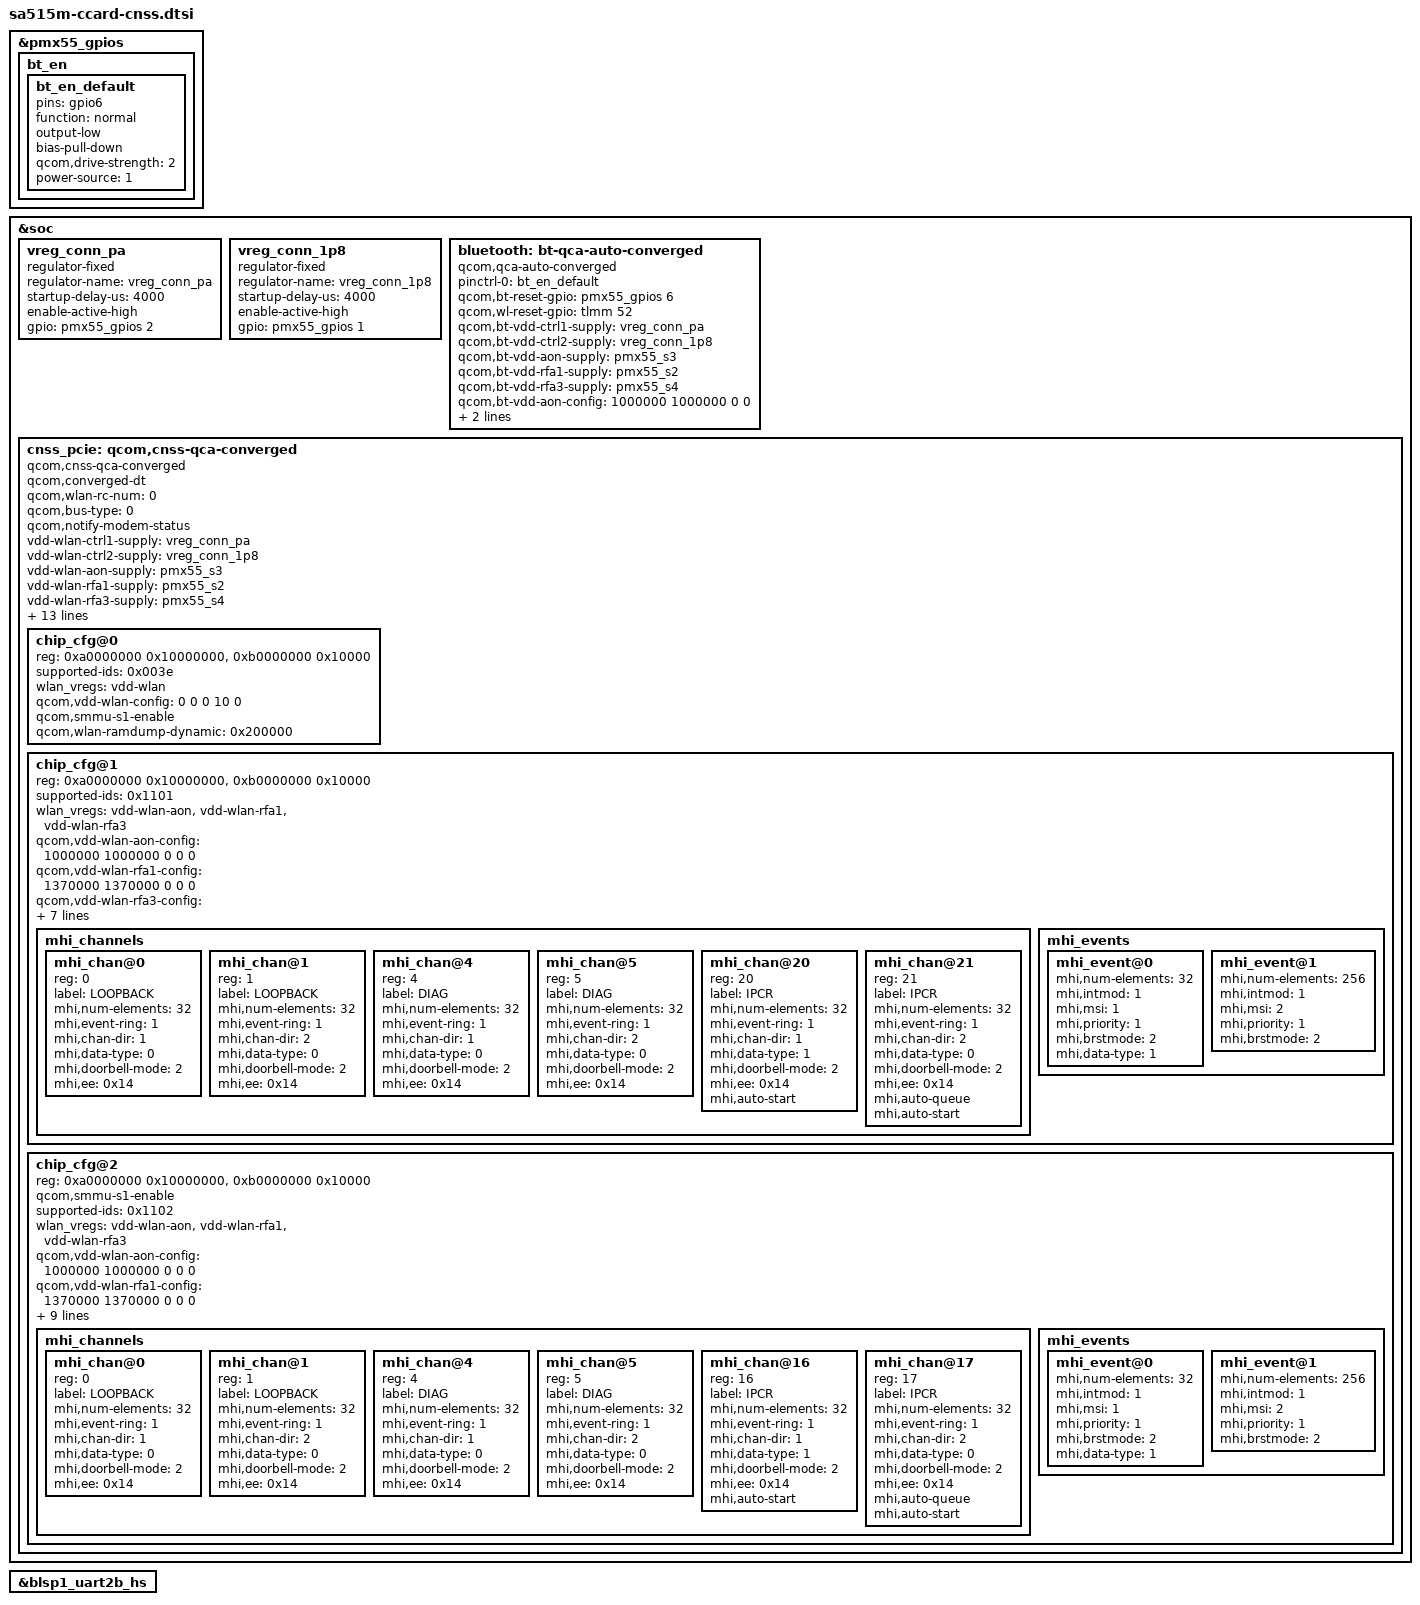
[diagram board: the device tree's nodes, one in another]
#include "pmx55.dtsi"
#include <dt-bindings/pinctrl/qcom,pmic-gpio.h>

&pmx55_gpios {

	bt_en {
		bt_en_default: bt_en_default {
			pins = "gpio6";
			function = "normal";
			output-low;
			bias-pull-down;
			qcom,drive-strength = <2>;
			power-source = <1>;
		};
	};
};

&soc {

	vreg_conn_pa: vreg_conn_pa {
		compatible = "regulator-fixed";
		regulator-name = "vreg_conn_pa";
		startup-delay-us = <4000>;
		enable-active-high;
		gpio = <&pmx55_gpios 2 GPIO_ACTIVE_HIGH>;
	};

	vreg_conn_1p8: vreg_conn_1p8 {
		compatible = "regulator-fixed";
		regulator-name = "vreg_conn_1p8";
		startup-delay-us = <4000>;
		enable-active-high;
		gpio = <&pmx55_gpios 1 GPIO_ACTIVE_HIGH>;
	};

	bluetooth: bt-qca-auto-converged {
		compatible = "qcom,qca-auto-converged";
		pinctrl-names = "default";
		pinctrl-0 = <&bt_en_default>;
		qcom,bt-reset-gpio = <&pmx55_gpios 6 0>;
		qcom,wl-reset-gpio = <&tlmm 52 0>;

		qcom,bt-vdd-ctrl1-supply = <&vreg_conn_pa>;
		qcom,bt-vdd-ctrl2-supply = <&vreg_conn_1p8>;
		qcom,bt-vdd-aon-supply  = <&pmx55_s3>;
		qcom,bt-vdd-rfa1-supply = <&pmx55_s2>;
		qcom,bt-vdd-rfa3-supply = <&pmx55_s4>;

		qcom,bt-vdd-aon-config  = <1000000 1000000 0 0>;
		qcom,bt-vdd-rfa1-config = <1370000 1370000 0 0>;
		qcom,bt-vdd-rfa3-config = <1904000 1904000 0 0>;
	};

	cnss_pcie: qcom,cnss-qca-converged {
		compatible = "qcom,cnss-qca-converged";

		qcom,converged-dt;
		qcom,wlan-rc-num = <0>;
		qcom,bus-type=<0>;
		qcom,notify-modem-status;

		#address-cells=<1>;
		#size-cells=<1>;
		ranges = <0xa0000000 0xa0000000 0x10000000>,
			  <0xb0000000 0xb0000000 0x10000>;

		vdd-wlan-ctrl1-supply = <&vreg_conn_pa>;
		vdd-wlan-ctrl2-supply = <&vreg_conn_1p8>;
		vdd-wlan-aon-supply = <&pmx55_s3>;
		vdd-wlan-rfa1-supply = <&pmx55_s2>;
		vdd-wlan-rfa3-supply = <&pmx55_s4>;

		wlan_vregs = "vdd-wlan-ctrl1", "vdd-wlan-ctrl2", "vdd-wlan-aon", "vdd-wlan-rfa1", "vdd-wlan-rfa3";
		qcom,vdd-wlan-ctrl1-config = <0 0 0 0 0>;
		qcom,vdd-wlan-ctrl2-config = <0 0 0 0 0>;
		qcom,vdd-wlan-aon-config = <1000000 1000000 0 0 0>;
		qcom,vdd-wlan-rfa1-config = <1370000 1370000 0 0 0>;
		qcom,vdd-wlan-rfa3-config = <1904000 1904000 450000 0 0>;
		wlan-en-gpio = <&tlmm 52 0>;
		pinctrl-names = "wlan_en_active", "wlan_en_sleep";
		pinctrl-0 = <&cnss_wlan_en_active>;
		pinctrl-1 = <&cnss_wlan_en_sleep>;

		chip_cfg@0 {
			reg = <0xa0000000 0x10000000>,
				<0xb0000000 0x10000>;
			reg-names = "smmu_iova_base", "smmu_iova_ipa";

			supported-ids = <0x003e>;
			wlan_vregs = "vdd-wlan";
			qcom,vdd-wlan-config = <0 0 0 10 0>;

			qcom,smmu-s1-enable;
			qcom,wlan-ramdump-dynamic = <0x200000>;
		};

		chip_cfg@1 {
			reg = <0xa0000000 0x10000000>,
				<0xb0000000 0x10000>;
			reg-names = "smmu_iova_base", "smmu_iova_ipa";

			supported-ids = <0x1101>;
			wlan_vregs = "vdd-wlan-aon", "vdd-wlan-rfa1",
				"vdd-wlan-rfa3";

			qcom,vdd-wlan-aon-config = <1000000 1000000 0 0 0>;
			qcom,vdd-wlan-rfa1-config = <1370000 1370000 0 0 0>;
			qcom,vdd-wlan-rfa3-config = <1904000 1904000 450000 0 0>;
			qcom,wlan-ramdump-dynamic = <0x400000>;
			mhi,max-channels = <30>;
			mhi,buffer-len = <0x8000>;
			mhi,timeout = <10000>;
			qcom,smmu-s1-enable;
			pcie-disable-l1ss;
			mhi_channels {
				#address-cells = <1>;
				#size-cells = <0>;
				mhi_chan@0 {
					reg = <0>;
					label = "LOOPBACK";
					mhi,num-elements = <32>;
					mhi,event-ring = <1>;
					mhi,chan-dir = <1>;
					mhi,data-type = <0>;
					mhi,doorbell-mode = <2>;
					mhi,ee = <0x14>;
				};

				mhi_chan@1 {
					reg = <1>;
					label = "LOOPBACK";
					mhi,num-elements = <32>;
					mhi,event-ring = <1>;
					mhi,chan-dir = <2>;
					mhi,data-type = <0>;
					mhi,doorbell-mode = <2>;
					mhi,ee = <0x14>;
				};

				mhi_chan@4 {
					reg = <4>;
					label = "DIAG";
					mhi,num-elements = <32>;
					mhi,event-ring = <1>;
					mhi,chan-dir = <1>;
					mhi,data-type = <0>;
					mhi,doorbell-mode = <2>;
					mhi,ee = <0x14>;
				};

				mhi_chan@5 {
					reg = <5>;
					label = "DIAG";
					mhi,num-elements = <32>;
					mhi,event-ring = <1>;
					mhi,chan-dir = <2>;
					mhi,data-type = <0>;
					mhi,doorbell-mode = <2>;
					mhi,ee = <0x14>;
				};

				mhi_chan@20 {
					reg = <20>;
					label = "IPCR";
					mhi,num-elements = <32>;
					mhi,event-ring = <1>;
					mhi,chan-dir = <1>;
					mhi,data-type = <1>;
					mhi,doorbell-mode = <2>;
					mhi,ee = <0x14>;
					mhi,auto-start;
				};

				mhi_chan@21 {
					reg = <21>;
					label = "IPCR";
					mhi,num-elements = <32>;
					mhi,event-ring = <1>;
					mhi,chan-dir = <2>;
					mhi,data-type = <0>;
					mhi,doorbell-mode = <2>;
					mhi,ee = <0x14>;
					mhi,auto-queue;
					mhi,auto-start;
				};
			};

			mhi_events {
				mhi_event@0 {
					mhi,num-elements = <32>;
					mhi,intmod = <1>;
					mhi,msi = <1>;
					mhi,priority = <1>;
					mhi,brstmode = <2>;
					mhi,data-type = <1>;
				};

				mhi_event@1 {
					mhi,num-elements = <256>;
					mhi,intmod = <1>;
					mhi,msi = <2>;
					mhi,priority = <1>;
					mhi,brstmode = <2>;
				};
			};
		};

		chip_cfg@2 {
			reg = <0xa0000000 0x10000000>,
				<0xb0000000 0x10000>;
			reg-names = "smmu_iova_base", "smmu_iova_ipa";
			qcom,smmu-s1-enable;
			supported-ids = <0x1102>;
			wlan_vregs = "vdd-wlan-aon", "vdd-wlan-rfa1",
				"vdd-wlan-rfa3";

			qcom,vdd-wlan-aon-config = <1000000 1000000 0 0 0>;
			qcom,vdd-wlan-rfa1-config = <1370000 1370000 0 0 0>;
			qcom,vdd-wlan-rfa3-config = <1904000 1904000 0 0 0>;

			qcom,wlan-ramdump-dynamic = <0x300000>;
			mhi,max-channels = <30>;
			mhi,buffer-len = <0x8000>;
			mhi,timeout = <10000>;
			mhi,ee = <0x3>, <0x4>;
			mhi,ee-names = "SBL", "RDDM";
			mhi,bhie-offset = <0x0324>;
			mhi_channels {
				mhi_chan@0 {
					reg = <0>;
					label = "LOOPBACK";
					mhi,num-elements = <32>;
					mhi,event-ring = <1>;
					mhi,chan-dir = <1>;
					mhi,data-type = <0>;
					mhi,doorbell-mode = <2>;
					mhi,ee = <0x14>;
				};

				mhi_chan@1 {
					reg = <1>;
					label = "LOOPBACK";
					mhi,num-elements = <32>;
					mhi,event-ring = <1>;
					mhi,chan-dir = <2>;
					mhi,data-type = <0>;
					mhi,doorbell-mode = <2>;
					mhi,ee = <0x14>;
				};

				mhi_chan@4 {
					reg = <4>;
					label = "DIAG";
					mhi,num-elements = <32>;
					mhi,event-ring = <1>;
					mhi,chan-dir = <1>;
					mhi,data-type = <0>;
					mhi,doorbell-mode = <2>;
					mhi,ee = <0x14>;
				};

				mhi_chan@5 {
					reg = <5>;
					label = "DIAG";
					mhi,num-elements = <32>;
					mhi,event-ring = <1>;
					mhi,chan-dir = <2>;
					mhi,data-type = <0>;
					mhi,doorbell-mode = <2>;
					mhi,ee = <0x14>;
				};

				mhi_chan@16 {
					reg = <16>;
					label = "IPCR";
					mhi,num-elements = <32>;
					mhi,event-ring = <1>;
					mhi,chan-dir = <1>;
					mhi,data-type = <1>;
					mhi,doorbell-mode = <2>;
					mhi,ee = <0x14>;
					mhi,auto-start;
				};

				mhi_chan@17 {
					reg = <17>;
					label = "IPCR";
					mhi,num-elements = <32>;
					mhi,event-ring = <1>;
					mhi,chan-dir = <2>;
					mhi,data-type = <0>;
					mhi,doorbell-mode = <2>;
					mhi,ee = <0x14>;
					mhi,auto-queue;
					mhi,auto-start;
				};
			};

			mhi_events {
				mhi_event@0 {
					mhi,num-elements = <32>;
					mhi,intmod = <1>;
					mhi,msi = <1>;
					mhi,priority = <1>;
					mhi,brstmode = <2>;
					mhi,data-type = <1>;
				};

				mhi_event@1 {
					mhi,num-elements = <256>;
					mhi,intmod = <1>;
					mhi,msi = <2>;
					mhi,priority = <1>;
					mhi,brstmode = <2>;
				};
			};
		};
	};
};

&blsp1_uart2b_hs {
	status = "okay";
};
